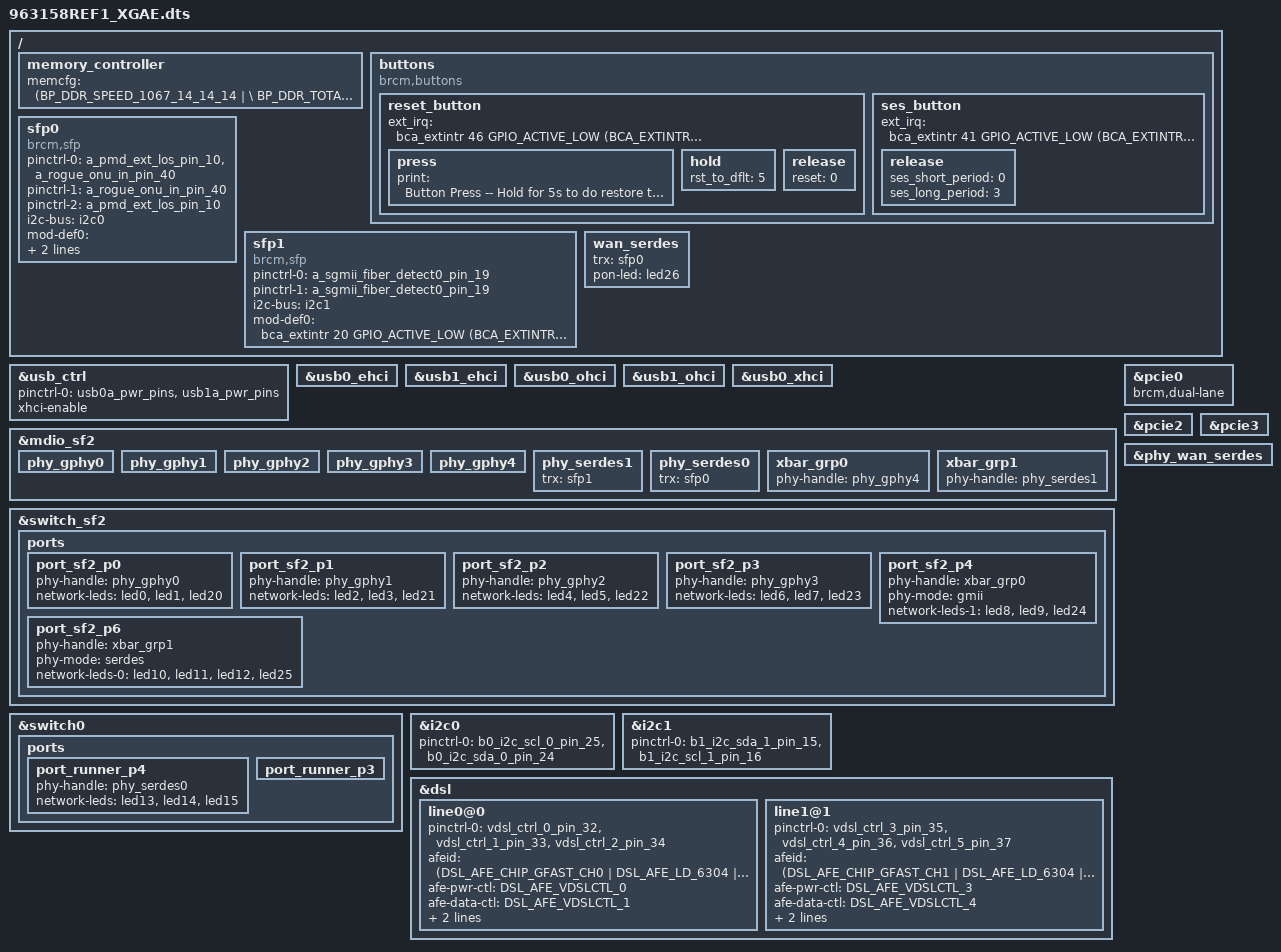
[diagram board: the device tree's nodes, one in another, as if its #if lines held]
#include "63158.dtsi"
#include "963158REF1_leds.dtsi"

/ {
    memory_controller {
        memcfg = <(BP_DDR_SPEED_1067_14_14_14 | \
                   BP_DDR_TOTAL_SIZE_1024MB   | \
                   BP_DDR_DEVICE_WIDTH_16     | \
                   BP_DDR_TOTAL_WIDTH_32BIT   | \
                   BP_DDR_SSC_CONFIG_1)>;
    };

	buttons {
		compatible = "brcm,buttons";
		reset_button {
			ext_irq = <&bca_extintr 46 GPIO_ACTIVE_LOW (BCA_EXTINTR_TYPE_LOW_LEVEL | BCA_EXTINTR_TYPE_SENSE_EDGE)>;
			press {
				print = "Button Press -- Hold for 5s to do restore to default";
			};
			hold {
				rst_to_dflt = <5>;
			};
			release {
				reset = <0>;
			};	
		};
		ses_button {
			ext_irq = <&bca_extintr 41 GPIO_ACTIVE_LOW (BCA_EXTINTR_TYPE_LOW_LEVEL | BCA_EXTINTR_TYPE_SENSE_EDGE)>;
			release {
				ses_short_period = <0>;
				ses_long_period = <3>;
			};
		};
	};

	sfp0: sfp0 {
		compatible = "brcm,sfp";
		pinctrl-names = "default", "tx-sd", "rx-sd";
		pinctrl-0 = <&a_pmd_ext_los_pin_10 &a_rogue_onu_in_pin_40>;
		pinctrl-1 = <&a_rogue_onu_in_pin_40>;
		pinctrl-2 = <&a_pmd_ext_los_pin_10>;

		i2c-bus = <&i2c0>;
		mod-def0 = <&bca_extintr 9 GPIO_ACTIVE_LOW (BCA_EXTINTR_TYPE_BOTH_EDGE | BCA_EXTINTR_TYPE_SENSE_EDGE)>;
		tx-power-gpio = <&gpioc 3 GPIO_ACTIVE_HIGH>;
	};

	sfp1: sfp1 {
		compatible = "brcm,sfp";
		pinctrl-names = "default", "rx-sd";
		pinctrl-0 = <&a_sgmii_fiber_detect0_pin_19>;
		pinctrl-1 = <&a_sgmii_fiber_detect0_pin_19>;

		i2c-bus = <&i2c1>;
		mod-def0 = <&bca_extintr 20 GPIO_ACTIVE_LOW (BCA_EXTINTR_TYPE_BOTH_EDGE | BCA_EXTINTR_TYPE_SENSE_EDGE)>;
	};

	wan_serdes {
            status = "okay";
		trx = <&sfp0>;
        pon-led = <&led26>;
	};
};

&usb_ctrl {
	pinctrl-names="default";
	pinctrl-0 = <&usb0a_pwr_pins &usb1a_pwr_pins>;
	status = "okay";
	xhci-enable;
};

&usb0_ehci {
	status = "okay";
};
&usb1_ehci {
	status = "okay";
};

&usb0_ohci {
	status = "okay";
};
&usb1_ohci {
	status = "okay";
};

&usb0_xhci {
	status = "okay";
};

&mdio_sf2 {
        /* Port PHY mapping:
            port_runner_p0  <-->  port_sf2_p8 -###- port_sf2_p0 <------------------> phy_gphy0
            port_runner_p1  <-->  port_sf2_p5 -# #- port_sf2_p1 <------------------> phy_gphy1
            port_runner_p2  <-->  port_sf2_p7 -# #- port_sf2_p2 <------------------> phy_gphy2
                                               # #- port_sf2_p3 <------------------> phy_gphy3
                                               # #- port_sf2_p4 <--> xbar_grp0 -+-+- phy_gphy4
                                               ###- port_sf2_p6 <--> xbar_grp1 -+-+- phy_serdes1 - sfp1       
                                              port_runner_p4/P3 <------------------> phy_serdes0 - sfp0 / PON
        */
	/* PHYs directly connected to SF2 */
	phy_gphy0 {
		status = "okay";
	};
	phy_gphy1 {
		status = "okay";
	};
	phy_gphy2 {
		status = "okay";
	};
	phy_gphy3 {
		status = "okay";
	};

	/* PHYs connected to crossbar */
	phy_gphy4 {
		status = "okay";
	};
	phy_serdes1 {
		trx = <&sfp1>;
		status = "okay";
	};

	/* PHY directly connected to Runner */
	phy_serdes0 {
		trx = <&sfp0>;
		status = "okay";
	};

	/* Crossbar groups */
	xbar_grp0 {
		phy-handle = <&phy_gphy4>;
		status = "okay";
	};
	xbar_grp1 {
		phy-handle = <&phy_serdes1>;
		status = "okay";
	};
};

&switch_sf2 {
	ports {
		port_sf2_p0 {
			phy-handle = <&phy_gphy0>;
			network-leds = <&led0 &led1 &led20>;
			status = "okay";
		};

		port_sf2_p1 {
			phy-handle = <&phy_gphy1>;
			network-leds = <&led2 &led3 &led21>;
			status = "okay";
		};

		port_sf2_p2 {
			phy-handle = <&phy_gphy2>;
			network-leds = <&led4 &led5 &led22>;
			status = "okay";
		};

		port_sf2_p3 {
			phy-handle = <&phy_gphy3>;
			network-leds = <&led6 &led7 &led23>;
			status = "okay";
		};

		port_sf2_p4 {
			phy-handle = <&xbar_grp0>;
			phy-mode = "gmii";
			/* xbar ext ep 1 sgphy leds */
			network-leds-1 = <&led8 &led9 &led24>;
			status = "okay";
		};

		port_sf2_p6 {
			phy-handle = <&xbar_grp1>;
			phy-mode = "serdes";
			/* xbar ext ep 0 serdes leds */
			network-leds-0 = <&led10 &led11 &led12 &led25>;
			status = "okay";
		};

	};
};

&switch0 {
		ports {
			
			port_runner_p4 {
				phy-handle = <&phy_serdes0>;
				network-leds = <&led13 &led14 &led15>;
				status = "okay";
			};

			port_runner_p3 {
				status = "okay";
			};

		};
};

&i2c0 {
	pinctrl-names = "default";
	pinctrl-0 = <&b0_i2c_scl_0_pin_25 &b0_i2c_sda_0_pin_24>;
	status = "okay";
};

&i2c1 {
	pinctrl-names = "default";
	pinctrl-0 = <&b1_i2c_sda_1_pin_15 &b1_i2c_scl_1_pin_16>;
	status = "okay";
};

&dsl {
	line0@0 {
		pinctrl-0 = <&vdsl_ctrl_0_pin_32 &vdsl_ctrl_1_pin_33 &vdsl_ctrl_2_pin_34>;
		pinctrl-names = "default";

		afeid = <(DSL_AFE_CHIP_GFAST_CH0 | DSL_AFE_LD_6304 | DSL_AFE_FE_REV_6304_REV_12_4_60)>;
		afe-pwr-ctl = <DSL_AFE_VDSLCTL_0>;
		afe-data-ctl = <DSL_AFE_VDSLCTL_1>;
		afe-clk-ctl = <DSL_AFE_VDSLCTL_2>;
		pwrboost-gpio = <&gpioc 38 GPIO_ACTIVE_HIGH>;
		status = "okay";
	};

	line1@1 {
		pinctrl-0 = <&vdsl_ctrl_3_pin_35 &vdsl_ctrl_4_pin_36 &vdsl_ctrl_5_pin_37>;
		pinctrl-names = "default";

		afeid = <(DSL_AFE_CHIP_GFAST_CH1 | DSL_AFE_LD_6304 | DSL_AFE_FE_REV_6304_REV_12_4_60)>;
		afe-pwr-ctl = <DSL_AFE_VDSLCTL_3>;
		afe-data-ctl = <DSL_AFE_VDSLCTL_4>;
		afe-clk-ctl = <DSL_AFE_VDSLCTL_5>;
		pwrboost-gpio = <&gpioc 38 GPIO_ACTIVE_HIGH>;
		status = "okay";
	};
};

#if defined(CONFIG_BCM_PCIE_HCD) || defined(CONFIG_BCM_PCIE_HCD_MODULE)
&pcie0 {
	brcm,dual-lane;
	status = "okay";
};
&pcie2 {
	status = "okay";
};
&pcie3 {
	status = "okay";
};
#endif //#if defined(CONFIG_BCM_PCIE_HCD) || defined(CONFIG_BCM_PCIE_HCD_MODULE)


&phy_wan_serdes {
    status = "okay";
};
